AUTOSAR XML (schema 00045)
package /Sed
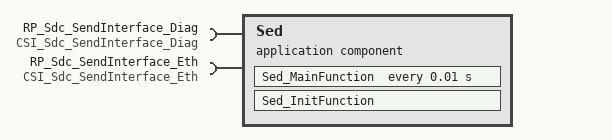
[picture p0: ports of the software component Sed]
  application sw component type Sed  # Soc Error Dection
    require port RP_Sdc_SendInterface_Diag: required-interface=CSI_Sdc_SendInterface_Diag
    require port RP_Sdc_SendInterface_Eth: required-interface=CSI_Sdc_SendInterface_Eth
    behavior Sed_IB: handle-termination-and-restart=NO-SUPPORT
      init event InitEvent_Sed_InitFunction: start-on-event=Sed_InitFunction
      timing event TimingEvent_Sed_MainFunction: start-on-event=Sed_MainFunction, period=0.01
      runnable Sed_InitFunction
      runnable Sed_MainFunction
        5 x sync call, all with timeout=0.0:
          scp_EthCableFault_Read: operation=RP_Sdc_SendInterface_Eth.EthCableFault_Read
          scp_EthCrcError_Read: operation=RP_Sdc_SendInterface_Eth.EthCrcError_Read
          scp_EthIcmpError_Read: operation=RP_Sdc_SendInterface_Eth.EthIcmpError_Read
          scp_EthSQI_Read: operation=RP_Sdc_SendInterface_Eth.EthSQI_Read
          scp_SocDiagInfo_Read: operation=RP_Sdc_SendInterface_Diag.SocDiagInfo_Read
  swc implementation SedImplementation: programming-language=C, sw-version=1.0.0, vendor-id=0, behavior=Sed_IB
    code-descriptors:
      code CodeGen: artifact-descriptors=[{short-label=SWHDR, category=SWHDR}, {short-label=SWSRC, category=SWSRC}]
    resource consumption Sed_Resource
      memory section CODE: sw-addrmethod=CODE
      memory section VAR_UNSPECIFIED: sw-addrmethod=VAR
